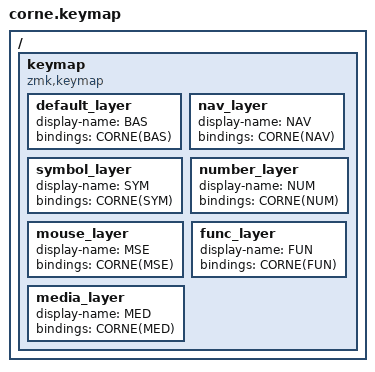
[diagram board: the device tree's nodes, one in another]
/*
 * Corne (3x6 + 엄지 3). 키는 config/keymap_common.dtsi 에서 고친다.
 */

#define LEFT_KEYS    0 1 2 3 4 5  12 13 14 15 16 17  24 25 26 27 28 29  36 37 38
#define RIGHT_KEYS   6 7 8 9 10 11  18 19 20 21 22 23  30 31 32 33 34 35  39 40 41
#define LEFT_THUMBS  36 37 38
#define RIGHT_THUMBS 39 40 41

#include "keymap_common.dtsi"

#define CORNE(...) CORNE_(__VA_ARGS__)
#define CORNE_(l0, r0, l1, r1, l2, r2, lt, rt) l0 r0 l1 r1 l2 r2 lt rt

/ {
    keymap {
        compatible = "zmk,keymap";

        default_layer {
            display-name = "BAS";
            bindings = <CORNE(BAS)>;
        };

        nav_layer {
            display-name = "NAV";
            bindings = <CORNE(NAV)>;
        };

        symbol_layer {
            display-name = "SYM";
            bindings = <CORNE(SYM)>;
        };

        number_layer {
            display-name = "NUM";
            bindings = <CORNE(NUM)>;
        };

        mouse_layer {
            display-name = "MSE";
            bindings = <CORNE(MSE)>;
        };

        func_layer {
            display-name = "FUN";
            bindings = <CORNE(FUN)>;
        };

        media_layer {
            display-name = "MED";
            bindings = <CORNE(MED)>;
        };

    };
};
